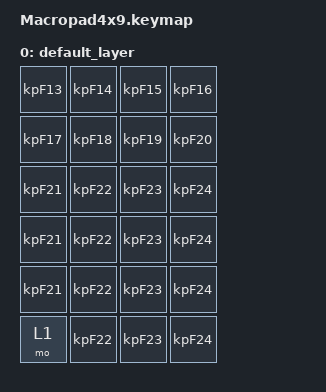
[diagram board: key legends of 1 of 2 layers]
#include <behaviors.dtsi>
#include <dt-bindings/zmk/keys.h>
#include <dt-bindings/zmk/bt.h>

/ {
    keymap {
        compatible = "zmk,keymap";

        default_layer {
            bindings = <
                &kp KP_F13   &kp KP_F14  &kp KP_F15   &kp KP_F16
                &kp KP_F17   &kp KP_F18  &kp KP_F19   &kp KP_F20
                &kp KP_F21   &kp KP_F22  &kp KP_F23   &kp KP_F24
                &kp KP_F21   &kp KP_F22  &kp KP_F23   &kp KP_F24
                &kp KP_F21   &kp KP_F22  &kp KP_F23   &kp KP_F24
                &mo 1        &kp KP_F22  &kp KP_F23   &kp KP_F24
                >;

        };

        bt_layer {
            bindings = <
            &none            &none          &bootloader
            &none            &none          &bt BT_CLR
            &bt BT_SEL 0     &bt BT_SEL 1   &bt BT_SEL 2
            >;
        };
    };
};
